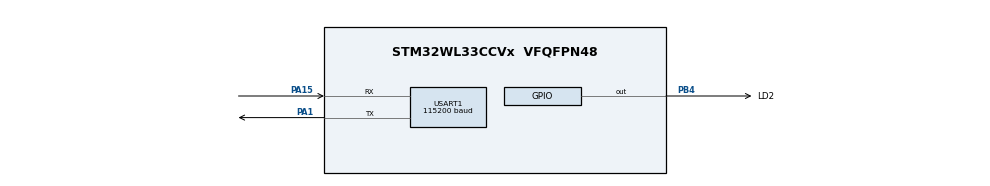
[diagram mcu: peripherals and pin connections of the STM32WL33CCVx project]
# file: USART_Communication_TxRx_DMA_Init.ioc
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Dma.Request0=USART1_TX
Dma.Request1=USART1_RX
Dma.USART1_RX.1.Direction=DMA_PERIPH_TO_MEMORY
Dma.USART1_RX.1.EventEnable=DISABLE
Dma.USART1_RX.1.FIFOMode=DMA_FIFOMODE_DISABLE
Dma.USART1_RX.1.Instance=DMA1_Channel3
Dma.USART1_RX.1.MDMA_Chaining=ENABLE
Dma.USART1_RX.1.Mandatory=DISABLE
Dma.USART1_RX.1.MemDataAlignment=DMA_MDATAALIGN_BYTE
Dma.USART1_RX.1.MemInc=DMA_MINC_ENABLE
Dma.USART1_RX.1.Mode=DMA_NORMAL
Dma.USART1_RX.1.PeriphDataAlignment=DMA_PDATAALIGN_BYTE
Dma.USART1_RX.1.PeriphInc=DMA_PINC_DISABLE
Dma.USART1_RX.1.Priority=DMA_PRIORITY_HIGH
Dma.USART1_RX.1.SignalID=HAL_DMAMUX1_REQ_GEN_EXTI0
Dma.USART1_RX.1.SyncEnable=DISABLE
Dma.USART1_RX.1.SyncRequestNumber=1
Dma.USART1_TX.0.Direction=DMA_MEMORY_TO_PERIPH
Dma.USART1_TX.0.EventEnable=DISABLE
Dma.USART1_TX.0.FIFOMode=DMA_FIFOMODE_DISABLE
Dma.USART1_TX.0.Instance=DMA1_Channel4
Dma.USART1_TX.0.MDMA_Chaining=ENABLE
Dma.USART1_TX.0.Mandatory=DISABLE
Dma.USART1_TX.0.MemDataAlignment=DMA_MDATAALIGN_BYTE
Dma.USART1_TX.0.MemInc=DMA_MINC_ENABLE
Dma.USART1_TX.0.Mode=DMA_NORMAL
Dma.USART1_TX.0.PeriphDataAlignment=DMA_PDATAALIGN_BYTE
Dma.USART1_TX.0.PeriphInc=DMA_PINC_DISABLE
Dma.USART1_TX.0.Priority=DMA_PRIORITY_HIGH
Dma.USART1_TX.0.SignalID=HAL_DMAMUX1_REQ_GEN_EXTI0
Dma.USART1_TX.0.SyncEnable=DISABLE
Dma.USART1_TX.0.SyncRequestNumber=1
Mcu.Family=STM32WL3
Mcu.Name=STM32WL33CCVx
Mcu.Package=VFQFPN48
NVIC.DMA_IRQn=true\:0\:0\:false\:false\:true\:false\:true\:true
NVIC.USART1_IRQn=true\:0\:0\:false\:false\:true\:true\:true\:true
OSCIN.Mode=HSE-External-Oscillator
OSCIN.Signal=RCC_OSC_IN
OSCOUT.Mode=HSE-External-Oscillator
OSCOUT.Signal=RCC_OSC_OUT
PA1.GPIO_PuPd=GPIO_PULLUP
PA1.GPIO_Speed=GPIO_SPEED_FREQ_HIGH
PA1.Mode=Asynchronous
PA1.Signal=USART1_TX
PA15.GPIO_PuPd=GPIO_PULLUP
PA15.GPIO_Speed=GPIO_SPEED_FREQ_HIGH
PA15.Mode=Asynchronous
PA15.Signal=USART1_RX
PB4.GPIO_Label=LD2
PB4.GPIO_PuPd=GPIO_NOPULL
PB4.Signal=GPIO_Output
ProjectManager.HeapSize=0x000
ProjectManager.StackSize=0xC00
ProjectManager.TargetToolchain=EWARM V9.30
RCC.HSE_VALUE=48000000
RCC.HSI_VALUE=64000000
RCC.LSE_VALUE=32768
RCC.RC64MPLLSource=RCC_LSCOSOURCE_PLL64
USART1.AutoBaudRateEnableParam=UART_ADVFEATURE_AUTOBAUDRATE_DISABLE
USART1.BaudRate=115200
USART1.ClockPrescaler=PRESCALER_DIV1
USART1.DMADisableonRxErrorParam=ADVFEATURE_DMA_ENABLEONRXERROR
USART1.DataInvertParam=ADVFEATURE_DATAINV_DISABLE
USART1.FIFOMode=FIFOMODE_DISABLE
USART1.MSBFirstParam=ADVFEATURE_MSBFIRST_DISABLE
USART1.Mode=MODE_TX_RX
USART1.OneBitSampling=UART_ONE_BIT_SAMPLE_DISABLE
USART1.OverSampling=UART_OVERSAMPLING_16
USART1.OverrunDisableParam=ADVFEATURE_OVERRUN_ENABLE
USART1.Parity=PARITY_NONE
USART1.RXFIFOThreshold=RXFIFO_THRESHOLD_1EIGHTHFULL
USART1.RxPinLevelInvertParam=ADVFEATURE_RXINV_DISABLE
USART1.StopBits=STOPBITS_1
USART1.SwapParam=ADVFEATURE_SWAP_DISABLE
USART1.TXFIFOThreshold=TXFIFO_THRESHOLD_1EIGHTHFULL
USART1.TxPinLevelInvertParam=ADVFEATURE_TXINV_DISABLE
USART1.VirtualMode-Asynchronous=VM_ASYNC
USART1.WordLength=WORDLENGTH_8B
VP_PWR_VS_SECSignals.Mode=Security/Privilege
board=custom

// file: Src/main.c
/* USER CODE BEGIN Header */
/**
  ******************************************************************************
  * @file    Examples_LL/USART/USART_Communication_TxRx_DMA_Init/Src/main.c
  * @author  MCD Application Team
  * @brief   This example describes how to send/receive bytes over USART IP using
  *          the STM32WL3x USART LL API in DMA mode.
  *          Peripheral initialization done using LL unitary services functions.
  ******************************************************************************
  * @attention
  *
  * Copyright (c) 2024 STMicroelectronics.
  * All rights reserved.
  *
  * This software is licensed under terms that can be found in the LICENSE file
  * in the root directory of this software component.
  * If no LICENSE file comes with this software, it is provided AS-IS.
  *
  ******************************************************************************
  */
/* USER CODE END Header */
#include "main.h"

/* USER CODE BEGIN PV */

__IO uint8_t ubButtonPress = 0;
__IO uint8_t ubSend = 0;
/* Buffer used for transmission */
uint8_t aTxBuffer[] = "STM32WL3x USART LL API Example : TX/RX in DMA mode\r\nConfiguration UART 115200 bps, 8 data bit/1 stop bit/No parity/No HW flow control\r\nPlease enter 'END' string ...\r\n";
uint8_t ubNbDataToTransmit = sizeof(aTxBuffer);
__IO uint8_t ubTransmissionComplete = 0;

/* Buffer used for reception */
const uint8_t aStringToReceive[] = "END";
uint8_t ubNbDataToReceive = sizeof(aStringToReceive) - 1;
uint8_t aRxBuffer[sizeof(aStringToReceive) - 1];
__IO uint8_t ubReceptionComplete = 0;

/* USER CODE END PV */

void SystemClock_Config(void);
void PeriphCommonClock_Config(void);
static void MX_GPIO_Init(void);
static void MX_DMA_Init(void);
static void MX_USART1_UART_Init(void);
/* USER CODE BEGIN PFP */

void     StartTransfers(void);
void     LED_On(void);
void     LED_Blinking(uint32_t Period);
void     LED_Off(void);
void     UserButton_Init(void);
void     WaitForUserButtonPress(void);
void     WaitAndCheckEndOfTransfer(void);
uint8_t  Buffercmp8(uint8_t *pBuffer1, uint8_t *pBuffer2, uint8_t BufferLength);

/* USER CODE END PFP */

int main(void)
{

  /* MCU Configuration--------------------------------------------------------*/

  /* Reset of all peripherals, Initializes the Flash interface and the Systick. */
  LL_APB0_GRP1_EnableClock(LL_APB0_GRP1_PERIPH_SYSCFG);

  /* Configure the system clock */
  SystemClock_Config();

  /* Configure the peripherals common clocks */
  PeriphCommonClock_Config();

  /* USER CODE BEGIN SysInit */
  /* Initialize USER push-button in EXTI mode */
  UserButton_Init();
  /* USER CODE END SysInit */

  /* Initialize all configured peripherals */
  MX_GPIO_Init();
  MX_DMA_Init();
  MX_USART1_UART_Init();
  /* USER CODE BEGIN 2 */
  /* Wait for USER push-button press to start transfer */
  WaitForUserButtonPress();

  /* Initiate DMA transfers */
  StartTransfers();

  /* Wait for the end of the transfer and check received data */
  WaitAndCheckEndOfTransfer();

  /* USER CODE END 2 */

  /* Infinite loop */
  while (1)
  {

  }
}

void SystemClock_Config(void)
{

   /* Set HSE Capacitor Tuning */
  LL_RCC_HSE_SetCapacitorTuning(CFG_HW_RCC_HSE_CAPACITOR_TUNE);

   /* Set HSE startup Current */
 LL_RCC_HSE_SetStartupCurrent(0);

   /* Set HSE Amplitude Threshold */
 LL_RCC_HSE_SetAmplitudeThreshold(0);

   /* Set HSE Current Control */
  LL_RCC_HSE_SetCurrentControl(40);

   /* Enable the HSE */
  LL_RCC_HSE_Enable();

   /* Wait till HSE is ready */
  while(LL_RCC_HSE_IsReady() != 1)
  {
  }

  LL_FLASH_SetLatency(LL_FLASH_WAIT_STATES_1);

   /* Enable the RC64MPLL*/
  LL_RCC_RC64MPLL_Enable();

   /* Wait till RC64MPLL is ready */
  while(LL_RCC_RC64MPLL_IsReady() != 1)
  {
  }

  LL_RCC_SetRC64MPLLPrescaler(LL_RCC_RC64MPLL_DIV_1);

   /* Update the SystemCoreClock global variable */
  LL_SetSystemCoreClock(64000000);

   /* Configure the source of time base considering new system clocks settings*/
  LL_Init1msTick(64000000);
}

void PeriphCommonClock_Config(void)
{
  LL_RCC_SetSMPSPrescaler(LL_RCC_SMPS_DIV_2);

   /* Enable the KRM*/
  LL_RCC_KRM_Enable();
  LL_RCC_KRM_SetRateMultiplier(2);
}

static void MX_USART1_UART_Init(void)
{

  LL_USART_InitTypeDef USART_InitStruct = {0};

  LL_GPIO_InitTypeDef GPIO_InitStruct = {0};

  /* Peripheral clock enable */
  LL_APB1_GRP1_EnableClock(LL_APB1_GRP1_PERIPH_USART1);

  LL_AHB1_GRP1_EnableClock(LL_AHB1_GRP1_PERIPH_GPIOA);
  /**USART1 GPIO Configuration
  PA1   ------> USART1_TX
  PA15   ------> USART1_RX
  */
  GPIO_InitStruct.Pin = LL_GPIO_PIN_1|LL_GPIO_PIN_15;
  GPIO_InitStruct.Mode = LL_GPIO_MODE_ALTERNATE;
  GPIO_InitStruct.Speed = LL_GPIO_SPEED_FREQ_HIGH;
  GPIO_InitStruct.OutputType = LL_GPIO_OUTPUT_PUSHPULL;
  GPIO_InitStruct.Pull = LL_GPIO_PULL_UP;
  GPIO_InitStruct.Alternate = LL_GPIO_AF_1;
  LL_GPIO_Init(GPIOA, &GPIO_InitStruct);

  /* USART1 DMA Init */

  /* USART1_TX Init */
  LL_DMA_SetPeriphRequest(DMA1, LL_DMA_CHANNEL_4, LL_DMAMUX_REQ_USART1_TX);

  LL_DMA_SetDataTransferDirection(DMA1, LL_DMA_CHANNEL_4, LL_DMA_DIRECTION_MEMORY_TO_PERIPH);

  LL_DMA_SetChannelPriorityLevel(DMA1, LL_DMA_CHANNEL_4, LL_DMA_PRIORITY_HIGH);

  LL_DMA_SetMode(DMA1, LL_DMA_CHANNEL_4, LL_DMA_MODE_NORMAL);

  LL_DMA_SetPeriphIncMode(DMA1, LL_DMA_CHANNEL_4, LL_DMA_PERIPH_NOINCREMENT);

  LL_DMA_SetMemoryIncMode(DMA1, LL_DMA_CHANNEL_4, LL_DMA_MEMORY_INCREMENT);

  LL_DMA_SetPeriphSize(DMA1, LL_DMA_CHANNEL_4, LL_DMA_PDATAALIGN_BYTE);

  LL_DMA_SetMemorySize(DMA1, LL_DMA_CHANNEL_4, LL_DMA_MDATAALIGN_BYTE);

  /* USART1_RX Init */
  LL_DMA_SetPeriphRequest(DMA1, LL_DMA_CHANNEL_3, LL_DMAMUX_REQ_USART1_RX);

  LL_DMA_SetDataTransferDirection(DMA1, LL_DMA_CHANNEL_3, LL_DMA_DIRECTION_PERIPH_TO_MEMORY);

  LL_DMA_SetChannelPriorityLevel(DMA1, LL_DMA_CHANNEL_3, LL_DMA_PRIORITY_HIGH);

  LL_DMA_SetMode(DMA1, LL_DMA_CHANNEL_3, LL_DMA_MODE_NORMAL);

  LL_DMA_SetPeriphIncMode(DMA1, LL_DMA_CHANNEL_3, LL_DMA_PERIPH_NOINCREMENT);

  LL_DMA_SetMemoryIncMode(DMA1, LL_DMA_CHANNEL_3, LL_DMA_MEMORY_INCREMENT);

  LL_DMA_SetPeriphSize(DMA1, LL_DMA_CHANNEL_3, LL_DMA_PDATAALIGN_BYTE);

  LL_DMA_SetMemorySize(DMA1, LL_DMA_CHANNEL_3, LL_DMA_MDATAALIGN_BYTE);

  /* USART1 interrupt Init */
  NVIC_SetPriority(USART1_IRQn, 0);
  NVIC_EnableIRQ(USART1_IRQn);

  /* USER CODE BEGIN USART1_Init 1 */
  /* Configure the DMA functional parameters for transmission */
  LL_DMA_ConfigAddresses(DMA1, LL_DMA_CHANNEL_4,
                         (uint32_t)aTxBuffer,
                         LL_USART_DMA_GetRegAddr(USART1, LL_USART_DMA_REG_DATA_TRANSMIT),
                         LL_DMA_GetDataTransferDirection(DMA1, LL_DMA_CHANNEL_4));
  LL_DMA_SetDataLength(DMA1, LL_DMA_CHANNEL_4, ubNbDataToTransmit);

  /* Configure the DMA functional parameters for reception */
  LL_DMA_ConfigAddresses(DMA1, LL_DMA_CHANNEL_3,
                         LL_USART_DMA_GetRegAddr(USART1, LL_USART_DMA_REG_DATA_RECEIVE),
                         (uint32_t)aRxBuffer,
                         LL_DMA_GetDataTransferDirection(DMA1, LL_DMA_CHANNEL_3));
  LL_DMA_SetDataLength(DMA1, LL_DMA_CHANNEL_3, ubNbDataToReceive);

  /* Enable DMA transfer complete/error interrupts  */
  LL_DMA_EnableIT_TC(DMA1, LL_DMA_CHANNEL_4);
  LL_DMA_EnableIT_TE(DMA1, LL_DMA_CHANNEL_4);
  LL_DMA_EnableIT_TC(DMA1, LL_DMA_CHANNEL_3);
  LL_DMA_EnableIT_TE(DMA1, LL_DMA_CHANNEL_3);
  /* USER CODE END USART1_Init 1 */
  USART_InitStruct.PrescalerValue = LL_USART_PRESCALER_DIV1;
  USART_InitStruct.BaudRate = 115200;
  USART_InitStruct.DataWidth = LL_USART_DATAWIDTH_8B;
  USART_InitStruct.StopBits = LL_USART_STOPBITS_1;
  USART_InitStruct.Parity = LL_USART_PARITY_NONE;
  USART_InitStruct.TransferDirection = LL_USART_DIRECTION_TX_RX;
  USART_InitStruct.HardwareFlowControl = LL_USART_HWCONTROL_NONE;
  USART_InitStruct.OverSampling = LL_USART_OVERSAMPLING_16;
  LL_USART_Init(USART1, &USART_InitStruct);
  LL_USART_SetTXFIFOThreshold(USART1, LL_USART_FIFOTHRESHOLD_1_8);
  LL_USART_SetRXFIFOThreshold(USART1, LL_USART_FIFOTHRESHOLD_1_8);
  LL_USART_DisableFIFO(USART1);
  LL_USART_ConfigAsyncMode(USART1);

  LL_USART_Enable(USART1);

  /* Polling USART1 initialisation */
  while((!(LL_USART_IsActiveFlag_TEACK(USART1))) || (!(LL_USART_IsActiveFlag_REACK(USART1))))
  {
  }
  /* USER CODE BEGIN USART1_Init 2 */

  /* Polling USART initialisation */
  while ((!(LL_USART_IsActiveFlag_TEACK(USART1))) || (!(LL_USART_IsActiveFlag_REACK(USART1))))
  {
  }
  /* USER CODE END USART1_Init 2 */

}

static void MX_DMA_Init(void)
{

  /* Init with LL driver */
  /* DMA controller clock enable */
  LL_AHB1_GRP1_EnableClock(LL_AHB1_GRP1_PERIPH_DMA);

  /* DMA interrupt init */
  /* DMA_IRQn interrupt configuration */
  NVIC_SetPriority(DMA_IRQn, 0);
  NVIC_EnableIRQ(DMA_IRQn);

}

static void MX_GPIO_Init(void)
{
  LL_GPIO_InitTypeDef GPIO_InitStruct = {0};

  /* GPIO Ports Clock Enable */
  LL_AHB1_GRP1_EnableClock(LL_AHB1_GRP1_PERIPH_GPIOB);
  LL_AHB1_GRP1_EnableClock(LL_AHB1_GRP1_PERIPH_GPIOA);

  /**/
  LL_GPIO_ResetOutputPin(LD2_GPIO_Port, LD2_Pin);

  /**/
  GPIO_InitStruct.Pin = LD2_Pin;
  GPIO_InitStruct.Mode = LL_GPIO_MODE_OUTPUT;
  GPIO_InitStruct.Speed = LL_GPIO_SPEED_FREQ_LOW;
  GPIO_InitStruct.OutputType = LL_GPIO_OUTPUT_PUSHPULL;
  GPIO_InitStruct.Pull = LL_GPIO_PULL_NO;
  LL_GPIO_Init(LD2_GPIO_Port, &GPIO_InitStruct);

}

/* USER CODE BEGIN 4 */

/**
  * @brief  This function initiates TX and RX DMA transfers by enabling DMA channels
  * @param  None
  * @retval None
  */
void StartTransfers(void)
{
  /* Enable DMA RX Interrupt */
  LL_USART_EnableDMAReq_RX(USART1);

  /* Enable DMA TX Interrupt */
  LL_USART_EnableDMAReq_TX(USART1);

  /* Enable DMA Channel Rx */
  LL_DMA_EnableChannel(DMA1, LL_DMA_CHANNEL_3);

  /* Enable DMA Channel Tx */
  LL_DMA_EnableChannel(DMA1, LL_DMA_CHANNEL_4);
}

/**
  * @brief  Turn-on LD2.
  * @param  None
  * @retval None
  */
void LED_On(void)
{
  /* Turn LD2 on */
  LL_GPIO_ResetOutputPin(LD2_GPIO_Port, LD2_Pin);
}

/**
  * @brief  Turn-off LD2.
  * @param  None
  * @retval None
  */
void LED_Off(void)
{
  /* Turn LD2 off */
  LL_GPIO_SetOutputPin(LD2_GPIO_Port, LD2_Pin);
}

/**
  * @brief  Set LD2 to Blinking mode for an infinite loop (toggle period based on value provided as input parameter).
  * @param  Period : Period of time (in ms) between each toggling of LED
  *   This parameter can be user defined values. Pre-defined values used in that example are :
  *     @arg LED_BLINK_FAST : Fast Blinking
  *     @arg LED_BLINK_SLOW : Slow Blinking
  *     @arg LED_BLINK_ERROR : Error specific Blinking
  * @retval None
  */
void LED_Blinking(uint32_t Period)
{
  /* Toggle LD2 in an infinite loop */
  while (1)
  {
    LL_GPIO_TogglePin(LD2_GPIO_Port, LD2_Pin);
    LL_mDelay(Period);
  }
}

/**
  * @brief  Configures USER push-button in GPIO or EXTI Line Mode.
  * @param  None
  * @retval None
  */
void UserButton_Init(void)
{
  /* Enable the BUTTON Clock */
  USER_BUTTON_GPIO_CLK_ENABLE();

  /* Configure GPIO for BUTTON */

  LL_GPIO_SetPinPull(USER_BUTTON_GPIO_PORT, USER_BUTTON_PIN, LL_GPIO_PULL_UP);
  LL_EXTI_EnableIT(LL_EXTI_LINE_PA0);

  LL_GPIO_SetPinMode(USER_BUTTON_GPIO_PORT, USER_BUTTON_PIN, LL_GPIO_MODE_INPUT);

  /* Configure NVIC for USER_BUTTON_EXTI_IRQn */
  NVIC_SetPriority(USER_BUTTON_EXTI_IRQn, 3);
  NVIC_EnableIRQ(USER_BUTTON_EXTI_IRQn);

  LL_EXTI_EnableIT(LL_EXTI_LINE_PA0);

}

/**
  * @brief  Wait for USER push-button press to start transfer.
  * @param  None
  * @retval None
  */
/*  */
void WaitForUserButtonPress(void)
{
  while (ubButtonPress == 0)
  {
    LL_GPIO_TogglePin(LD2_GPIO_Port, LD2_Pin);
    LL_mDelay(LED_BLINK_FAST);
  }
  /* Ensure that LD2 is turned Off */
  LED_Off();
}

/**
  * @brief  Wait end of transfer and check if received Data are well.
  * @param  None
  * @retval None
  */
void WaitAndCheckEndOfTransfer(void)
{
  /* 1 - Wait end of transmission */
  while (ubTransmissionComplete != 1)
  {
  }
  /* Disable DMA1 Tx Channel */
  LL_DMA_DisableChannel(DMA1, LL_DMA_CHANNEL_4);

  /* 2 - Wait end of reception */
  while (ubReceptionComplete != 1)
  {
  }
  /* Disable DMA1 Rx Channel */
  LL_DMA_DisableChannel(DMA1, LL_DMA_CHANNEL_3);

  /* 3 - Compare received string to expected one */
  if (Buffercmp8((uint8_t *)aStringToReceive, (uint8_t *)aRxBuffer, ubNbDataToReceive))
  {
    /* Processing Error */
    LED_Blinking(LED_BLINK_ERROR);
  }
  else
  {
    /* Turn On Led if data are well received */
    LED_On();
  }
}

/**
* @brief Compares two 8-bit buffers and returns the comparison result.
* @param pBuffer1: pointer to the source buffer to be compared to.
* @param pBuffer2: pointer to the second source buffer to be compared to the first.
* @param BufferLength: buffer's length.
* @retval   0: Comparison is OK (the two Buffers are identical)
*           Value different from 0: Comparison is NOK (Buffers are different)
*/
uint8_t Buffercmp8(uint8_t *pBuffer1, uint8_t *pBuffer2, uint8_t BufferLength)
{
  while (BufferLength--)
  {
    if (*pBuffer1 != *pBuffer2)
    {
      return 1;
    }

    pBuffer1++;
    pBuffer2++;
  }

  return 0;
}

/******************************************************************************/
/*   USER IRQ HANDLER TREATMENT Functions                                     */
/******************************************************************************/
/**
  * @brief  Function to manage USER push-button
  * @param  None
  * @retval None
  */
void UserButton_Callback(void)
{
  /* Update USER push-button variable : to be checked in waiting loop in main program */
  ubButtonPress = 1;
}

/**
  * @brief  Function called from DMA1 IRQ Handler when Tx transfer is completed
  * @param  None
  * @retval None
  */
void DMA1_TransmitComplete_Callback(void)
{
  /* DMA Tx transfer completed */
  ubTransmissionComplete = 1;
}

/**
  * @brief  Function called from DMA1 IRQ Handler when Rx transfer is completed
  * @param  None
  * @retval None
  */
void DMA1_ReceiveComplete_Callback(void)
{
  /* DMA Rx transfer completed */
  ubReceptionComplete = 1;
}

/**
  * @brief  Function called in case of error detected in USART IT Handler
  * @param  None
  * @retval None
  */
void USART_TransferError_Callback(void)
{
  /* Disable DMA1 Tx Channel */
  LL_DMA_DisableChannel(DMA1, LL_DMA_CHANNEL_4);

  /* Disable DMA1 Rx Channel */
  LL_DMA_DisableChannel(DMA1, LL_DMA_CHANNEL_3);

  /* Set LD2 to Blinking mode to indicate error occurs */
  LED_Blinking(LED_BLINK_ERROR);
}

/* USER CODE END 4 */

void Error_Handler(void)
{
  while (1)
  {
  }
}
